# haltium_sysctrl register map
Vendor: Nordic Semiconductor; Series: nRFHaltium; File version: 1
Registers are 32-bit, read-write, reset 0x0 unless marked. A register's access mark holds for its fields unless they carry their own. Offsets are from the block's base; [hi:lo] are bit positions; lines under a group give offsets from that group; 'fields as' and 'values as' point back to an identical list.

## VDETAO1V8_S — VDETAO1V8
Base 0x5F971000
0x00 TASKS_PWRUP wo — Power up voltage detector
  [0] TASKS_PWRUP
    1=Trigger task
0x04 TASKS_PWRDOWN wo — Power down voltage detector
  [0] TASKS_PWRDOWN
    1=Trigger task
0x100 EVENTS_READY — Power up done
  [0] EVENTS_READY
    0=NotGenerated (Event not generated); 1=Generated (Event generated)
0x104 EVENTS_BROWNOUTHIGH — Brownout detector high level detected voltage below high threshold
  [0] EVENTS_BROWNOUTHIGH
    values as EVENTS_READY.EVENTS_READY
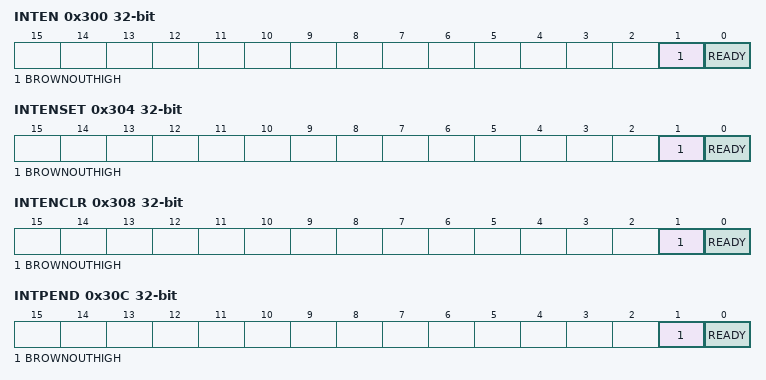
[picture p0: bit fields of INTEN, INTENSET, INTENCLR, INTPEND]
0x300 INTEN — Enable or disable interrupt
  [1] BROWNOUTHIGH — Enable or disable interrupt for event BROWNOUTHIGH
    0=Disabled; 1=Enabled
  [0] READY — Enable or disable interrupt for event READY
    0=Disabled; 1=Enabled
0x304 INTENSET — Enable interrupt
  [1] BROWNOUTHIGH — Write '1' to enable interrupt for event BROWNOUTHIGH
    on read: 0=Disabled (Read: Disabled); 1=Enabled (Read: Enabled) | on write: 1=Set (Enable)
  [0] READY — Write '1' to enable interrupt for event READY
    values as BROWNOUTHIGH
0x308 INTENCLR — Disable interrupt
  [1] BROWNOUTHIGH — Write '1' to disable interrupt for event BROWNOUTHIGH
    on read: 0=Disabled (Read: Disabled); 1=Enabled (Read: Enabled) | on write: 1=Clear (Disable)
  [0] READY — Write '1' to disable interrupt for event READY
    values as BROWNOUTHIGH
0x30C INTPEND ro — Pending interrupts
  [1] BROWNOUTHIGH — Read pending status of interrupt for event BROWNOUTHIGH
    on read: 0=NotPending (Read: Not pending); 1=Pending (Read: Pending)
  [0] READY — Read pending status of interrupt for event READY
    values as BROWNOUTHIGH
0x400 STATUS ro — Voltage detector status
  [1:0] MODE — Current voltage detector mode
    0=High power mode; 1=Low power mode; 2=Ultra-low power refresh mode
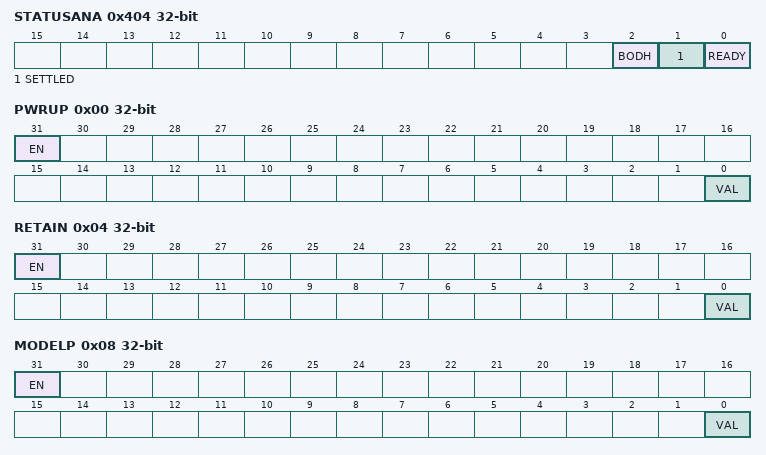
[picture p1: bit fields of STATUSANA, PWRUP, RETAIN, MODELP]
0x404 STATUSANA ro — Status of analog module output signals
  [2] BODH — Current value of the BODH signal from the analog module
  [1] SETTLED — Current value of the SETTLED signal from the analog module
  [0] READY — Current value of the READY signal from the analog module
0x410 CONFIG group — Unspecified
  0x00 CFG — Voltage detector configuration
    [1:0] BROWNOUTHIGHHYST — Brown out detector high level hysteresis voltage value
      0=Val0V020 (Hysteresis voltage is 20mV); 1=Val0V040 (Hysteresis voltage is 40mV); 2=Val0V000 (Hysteresis voltage is 0mV); 3=Val0V010 (Hysteresis voltage is 10mV)
  0x04 BROWNOUTCONFIG — Brown out detector configuration
    [0] ENBROWNOUTLVLLOW — Enable Brown out detector low level
      0=Disabled (Brown out detector low level is disabled); 1=Enabled (Brown out detector low level is enabled)
0x440 TRIM group — Unspecified
  0x00 BROWNOUTLVLHIGH — Brown out detector high threshold voltage level
    [5:0] VAL — Threshold voltage value.
  0x04 BROWNOUTLVLLOW — Brown out detector low threshold voltage level
    [5:0] VAL — Threshold voltage value.
0x480 MIRROR reset 0x1 — Enable LOCK for mirrored registers
  [0] LOCK — Lock for mirrored registers
    0=Disabled (Lock disabled); 1=Enabled (Lock enabled)
0x484 MODE — Voltage detector mode
  [2:0] MODE
    0=Automatically handled by the MMI; 1=High power mode; 2=Low power mode; 3=Ultra-low power refresh mode
0x500 OVERRIDE group — Unspecified
  0x00 PWRUP — Override the PWRUP signal to the analog module
    [31] EN — Enable the override
      0=Disabled (Override is disabled); 1=Enabled (Override is enabled)
    [0] VAL — Override value for the signal
  0x04 RETAIN — Override the RETAIN signal to the analog module
    fields as OVERRIDE.PWRUP
  0x08 MODELP — Override the MODE_LP signal to the analog module
    fields as OVERRIDE.PWRUP
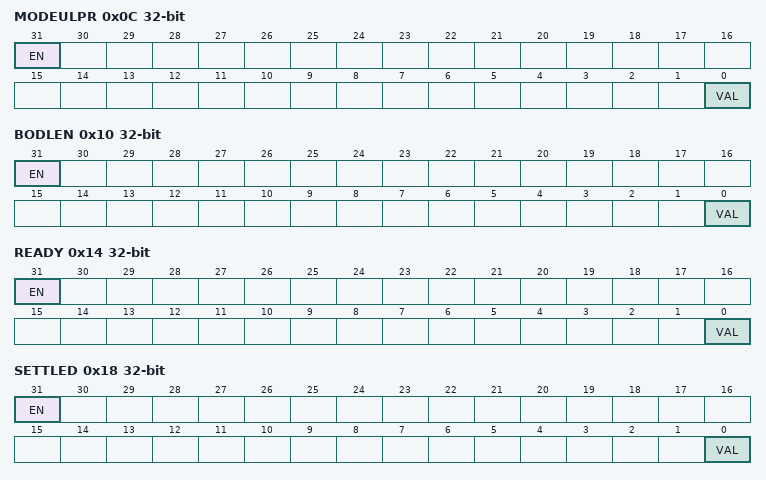
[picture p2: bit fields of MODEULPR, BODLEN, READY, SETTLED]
  0x0C MODEULPR — Override the MODE_ULPR signal to the analog module
    fields as OVERRIDE.PWRUP
  0x10 BODLEN — Override the BODL_EN signal to the analog module
    fields as OVERRIDE.PWRUP
  0x14 READY — Override the READY signal from the analog module
    [31] EN — Enable the override
      values as OVERRIDE.PWRUP.EN
    [0] VAL — Current value of the signal
  0x18 SETTLED — Override the SETTLED signal from the analog module
    fields as OVERRIDE.READY
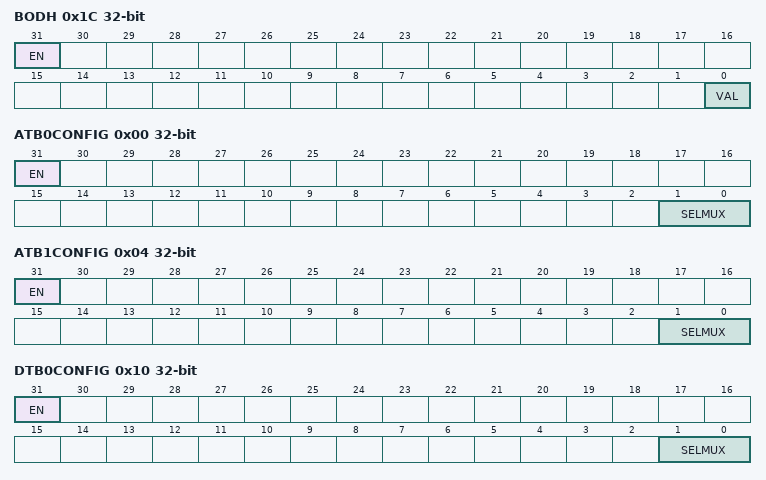
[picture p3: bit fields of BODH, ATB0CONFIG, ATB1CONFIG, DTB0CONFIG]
  0x1C BODH — Override the BODH signal from the analog module
    fields as OVERRIDE.READY
0x600 DFT group — Unspecified
  0x00 ATB0CONFIG — Analog Test Bus 0 (ATB0) configuration
    [31] EN — Enable the analog test bus
      0=Disabled (Analog test bus is disabled); 1=Enabled (Analog test bus is enabled)
    [1:0] SELMUX — Select multiplexer for ATB0
      0=HiZ; 1=VSS (Connect VSS); 3=Connect sense voltage for BOD comparators
  0x04 ATB1CONFIG — Analog Test Bus 1 (ATB1) configuration
    [31] EN — Enable the analog test bus
      values as DFT.ATB0CONFIG.EN
    [1:0] SELMUX — Select multiplexer for ATB1
      0=HiZ; 2=VREFH (Connect VREFH); 3=VREFL (Connect VREFL)
  0x10 DTB0CONFIG — Digital Test Bus 0 (DTB0) configuration
    [31] EN — Enable the digital test bus
      0=Disabled (Digital test bus is disabled); 1=Enabled (Digital test bus is enabled)
    [1:0] SELMUX — Select multiplexer for DTB0
      0=None selected; 1=Settled; 2=BODLCompOutput (BODL comparator output)
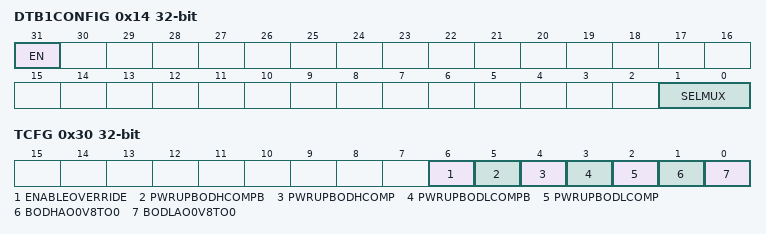
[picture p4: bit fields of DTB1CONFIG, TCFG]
  0x14 DTB1CONFIG — Digital Test Bus 1 (DTB1) configuration
    [31] EN — Enable the digital test bus
      values as DFT.DTB0CONFIG.EN
    [1:0] SELMUX — Select multiplexer for DTB1
      0=None selected; 1=Ready; 2=BODHCompOutput (BODH comparator output)
  0x1C DTB3CONFIG — Digital Test Bus 3 (DTB3) configuration
    [30] PWRUPDELTEST — Enable the PWRUP delay test circuit
      0=Disabled (PWRUP delay test circuit is disabled); 1=Enabled (PWRUP delay test circuit is enabled)
  0x30 TCFG — Test mode configuration
    [6] ENABLEOVERRIDE — Enable bits [5:2] above for overriding internal controls
      0=Disabled (Overriding internal controls disabled); 1=Enabled (Overriding internal controls enabled)
    [5] PWRUPBODHCOMPB — Power-up signal for BODH comparator bias
      0=Disabled (Power-up disabled); 1=Enabled (Power-up enabled)
    [4] PWRUPBODHCOMP — Power-up signal for BODH comparator
      0=Disabled (Power-up disabled); 1=Enabled (Power-up enabled)
    [3] PWRUPBODLCOMPB — Power-up signal for BODL comparator bias
      0=Disabled (Power-up disabled); 1=Enabled (Power-up enabled)
    [2] PWRUPBODLCOMP — Power-up signal for BODL comparator
      0=Disabled (Power-up disabled); 1=Enabled (Power-up enabled)
    [1] BODHAO0V8TO0 — Force BODH_AO_0V8 to 0
      0=Disabled (Override disabled); 1=Enabled (Override enabled)
    [0] BODLAO0V8TO0 — Force BODL_AO_0V8 to 0
      0=Disabled (Force disabled); 1=Enabled (Force enabled)
